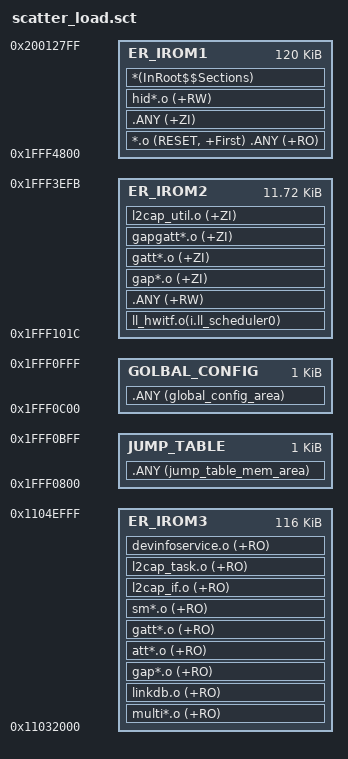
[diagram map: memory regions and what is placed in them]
; *************************************************************
; *** Scatter-Loading Description File generated by uVision ***
; *************************************************************

 LR_IROM1 0x1fff4800 0x0001e000 {  ; load region size_region
  ER_IROM1 0x1fff4800 0x0001e000  {  ; load address = execution address
	*.o (RESET, +First)  .ANY (+RO)  
	.ANY (+ZI)
	hid*.o (+RW)
	*(InRoot$$Sections)
}


;  ER_IROM2 0x1fff1200 0x00002d00  {  ; load address = execution address
	ER_IROM2 0x1fff101C 0x00002EE0  {  ; load address = execution address
	ll_hwitf.o(i.ll_scheduler0)
	.ANY (+RW)
	gap*.o     			(+ZI)
	gatt*.o    			(+ZI)
	gapgatt*.o       	(+ZI)
	l2cap_util.o		(+ZI)
	;gap_centdevmgr.o	(+RO)
  }
 } 
 
LR_IROM4  0x1fff0800 0x00800 {
  JUMP_TABLE 0x1fff0800 0x00400  {
   .ANY (jump_table_mem_area)	
  }
  GOLBAL_CONFIG 0x1fff0c00 0x00400  {
   .ANY (global_config_area) 
  }  
 } 

;LR_IROM3  0x11032000 0x030000 {
;  ER_IROM3 0x11032000 0x030000  {  ; load address = execution address
LR_IROM3  0x11032000 0x01D000 {
  ER_IROM3 0x11032000 0x01D000  {  ; load address = execution address
	multi*.o			(+RO)
	linkdb.o			(+RO)		; host code
	gap*.o     			(+RO)
	att*.o  			(+RO)
	gatt*.o    			(+RO)
	sm*.o				(+RO)
	l2cap_if.o          (+RO)
	l2cap_task.o        (+RO)
	devinfoservice.o	(+RO)
  }	
 }
 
